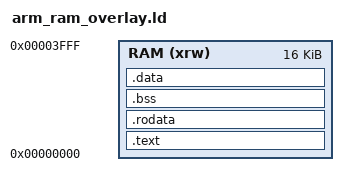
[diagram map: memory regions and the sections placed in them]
MEMORY
{
  RAM (xrw)      : ORIGIN = 0x00000000, LENGTH = 16K
}

SECTIONS
{
  .text :
  {
    . = ALIGN(4);
    *(.text)           /* .text sections (code) */
    *(.text*)          /* .text* sections (code) */
    *(.glue_7)         /* glue arm to thumb code */
    *(.glue_7t)        /* glue thumb to arm code */
    *(.eh_frame)

    KEEP (*(.init))
    KEEP (*(.fini))

    . = ALIGN(4);
  } >RAM

  .rodata :
  {
    . = ALIGN(4);
    *(.rodata)         /* .rodata sections (constants, strings, etc.) */
    *(.rodata*)        /* .rodata* sections (constants, strings, etc.) */
    . = ALIGN(4);
  } >RAM

  .bss :
  {
     . = ALIGN(4);
    *(.bss)
    *(.bss*)
    . = ALIGN(4);
  } >RAM

  .data : 
  {
    . = ALIGN(4);
    *(.data)           /* .data sections */
    *(.data*)          /* .data* sections */
    . = ALIGN(4);
  } >RAM

  /* Remove information from the standard libraries */
  /DISCARD/ :
  {
    libc.a ( * )
    libm.a ( * )
    libgcc.a ( * )
  }
}


